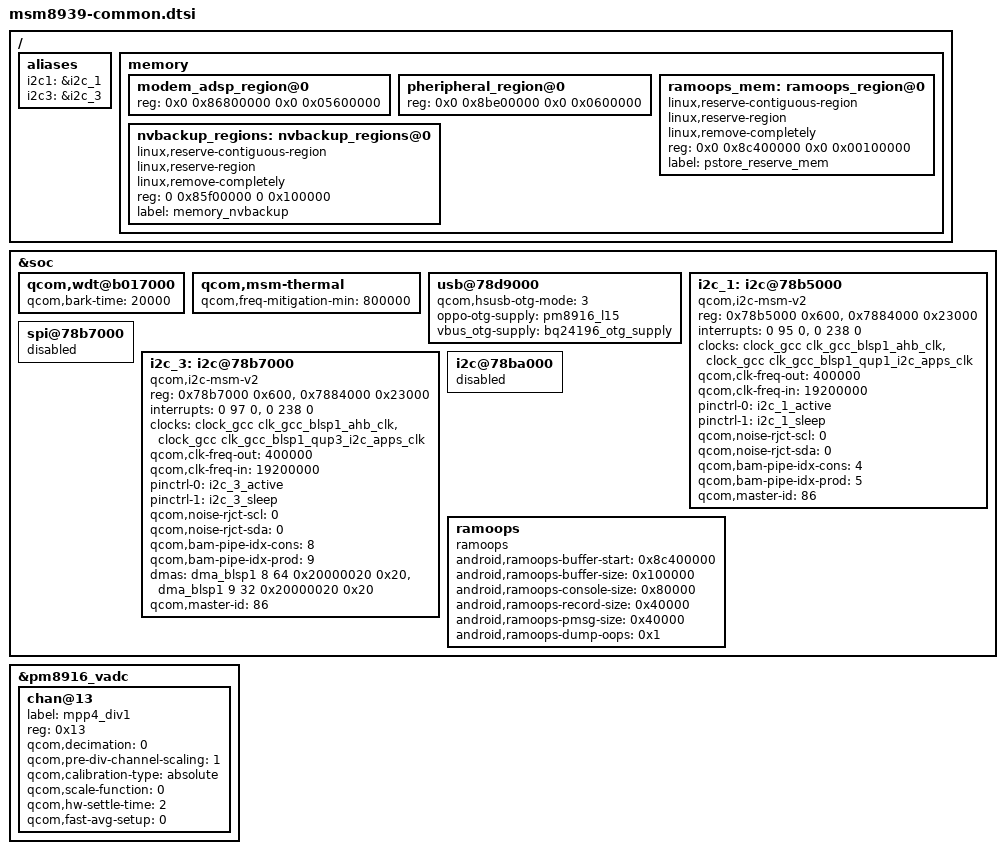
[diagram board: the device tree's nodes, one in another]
/* Copyright (c) 2014-2015, The Linux Foundation. All rights reserved.
 *
 * This program is free software; you can redistribute it and/or modify
 * it under the terms of the GNU General Public License version 2 and
 * only version 2 as published by the Free Software Foundation.
 *
 * This program is distributed in the hope that it will be useful,
 * but WITHOUT ANY WARRANTY; without even the implied warranty of
 * MERCHANTABILITY or FITNESS FOR A PARTICULAR PURPOSE.  See the
 * GNU General Public License for more details.
 */

/ {
	aliases {
		i2c1 = &i2c_1;
		i2c3 = &i2c_3;
	};

	memory {
		modem_adsp_region@0 {
			reg = <0x0 0x86800000 0x0 0x05600000>;
		};

		pheripheral_region@0 {
			reg = <0x0 0x8be00000 0x0 0x0600000>;
		};

		ramoops_mem: ramoops_region@0 {
			linux,reserve-contiguous-region;
			linux,reserve-region;
			linux,remove-completely;
			reg = <0x0 0x8c400000 0x0 0x00100000>;
			label = "pstore_reserve_mem";
		};

		nvbackup_regions: nvbackup_regions@0 {
			linux,reserve-contiguous-region;
			linux,reserve-region;
			linux,remove-completely;
			reg = <0 0x85f00000 0 0x100000>;
			label = "memory_nvbackup";
		};
	};
};

&soc {
	qcom,wdt@b017000 {
		qcom,bark-time = <20000>;
	};

	qcom,msm-thermal {
		qcom,freq-mitigation-min = <800000>;
	};

	usb@78d9000 {
		qcom,hsusb-otg-mode = <3>;
		oppo-otg-supply = <&pm8916_l15>;
		vbus_otg-supply = <&bq24196_otg_supply>;
	};

	i2c_1: i2c@78b5000 { /* BLSP1 QUP1 */
		compatible = "qcom,i2c-msm-v2";
		#address-cells = <1>;
		#size-cells = <0>;
		reg-names = "qup_phys_addr", "bam_phys_addr";
		reg = <0x78b5000 0x600>,
		      <0x7884000 0x23000>;
		interrupt-names = "qup_irq", "bam_irq";
		interrupts = <0 95 0>, <0 238 0>;
		clocks = <&clock_gcc clk_gcc_blsp1_ahb_clk>,
			 <&clock_gcc clk_gcc_blsp1_qup1_i2c_apps_clk>;
		clock-names = "iface_clk", "core_clk";
		qcom,clk-freq-out = <400000>;
		qcom,clk-freq-in  = <19200000>;
		pinctrl-names = "i2c_active", "i2c_sleep";
		pinctrl-0 = <&i2c_1_active>;
		pinctrl-1 = <&i2c_1_sleep>;
		qcom,noise-rjct-scl = <0>;
		qcom,noise-rjct-sda = <0>;
		qcom,bam-pipe-idx-cons = <4>;
		qcom,bam-pipe-idx-prod = <5>;
		qcom,master-id = <86>;
	};

	spi@78b7000 { /* BLSP1 QUP3 */
		status = "disabled";
	};

	i2c_3: i2c@78b7000 { /* BLSP1 QUP3 */
		compatible = "qcom,i2c-msm-v2";
		#address-cells = <1>;
		#size-cells = <0>;
		reg-names = "qup_phys_addr", "bam_phys_addr";
		reg = <0x78b7000 0x600>,
		      <0x7884000 0x23000>;
		interrupt-names = "qup_irq", "bam_irq";
		interrupts = <0 97 0>, <0 238 0>;
		clocks = <&clock_gcc clk_gcc_blsp1_ahb_clk>,
			 <&clock_gcc clk_gcc_blsp1_qup3_i2c_apps_clk>;
		clock-names = "iface_clk", "core_clk";
		qcom,clk-freq-out = <400000>;
		qcom,clk-freq-in  = <19200000>;
		pinctrl-names = "i2c_active", "i2c_sleep";
		pinctrl-0 = <&i2c_3_active>;
		pinctrl-1 = <&i2c_3_sleep>;
		qcom,noise-rjct-scl = <0>;
		qcom,noise-rjct-sda = <0>;
		qcom,bam-pipe-idx-cons = <8>;
		qcom,bam-pipe-idx-prod = <9>;
		dmas = <&dma_blsp1 8 64 0x20000020 0x20>,
		       <&dma_blsp1 9 32 0x20000020 0x20>;
		dma-names = "tx", "rx";
		qcom,master-id = <86>;
	};

	i2c@78ba000 { /* BLSP1 QUP6 */
		status = "disabled";
	};

	ramoops {
		compatible = "ramoops";
		status = "okay";

		android,ramoops-buffer-start = <0x8c400000>;
		android,ramoops-buffer-size = <0x100000>;
		android,ramoops-console-size = <0x80000>;
		android,ramoops-record-size = <0x40000>;
		android,ramoops-pmsg-size = <0x40000>;
		android,ramoops-dump-oops = <0x1>;
	};
};

&pm8916_vadc {
	chan@13 {
		label = "mpp4_div1";
		reg = <0x13>;
		qcom,decimation = <0>;
		qcom,pre-div-channel-scaling = <1>;
		qcom,calibration-type = "absolute";
		qcom,scale-function = <0>;
		qcom,hw-settle-time = <2>;
		qcom,fast-avg-setup = <0>;
	};
};
